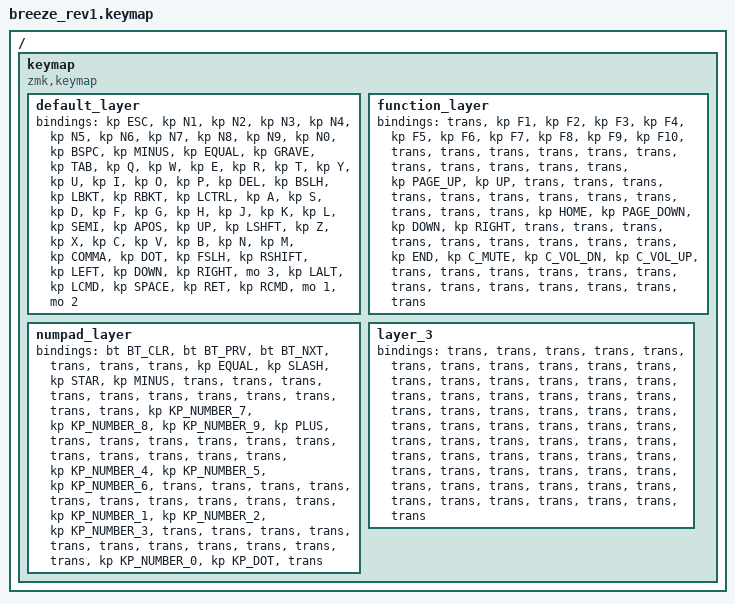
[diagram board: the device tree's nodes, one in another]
/*
 * Copyright (c) 2022 The ZMK Contributors
 *
 * SPDX-License-Identifier: MIT
 */

#include <behaviors.dtsi>
#include <dt-bindings/zmk/bt.h>
#include <dt-bindings/zmk/keys.h>

/ {
    keymap {
        compatible = "zmk,keymap";

        default_layer {
            // Ref: https://zmkfirmware.dev/docs/codes/
            // ---  MAIN  -----------------------------------------------------------------------------------------------------------------------
            // |    ESC    |     1     |     2     |     3      |      4      |      5     |                           |      6      |      7     |      8      |      9     |     0    |    BSPC    | |    -/_    |     =/+     |    GRAVE    |
            // |    TAB    |     Q     |     W     |     E      |      R      |      T     |                           |      Y      |      U     |      I      |      O     |     P    |    DEL     | |     \     |      [      |      ]      |
            // |   LCTRL   |     A     |     S     |     D      |      F      |      G     |                           |      H      |      J     |      K      |      L     |     ;    |     '      | |           |      UP     |             |
            // |   SHIFT   |     Z     |     X     |     C      |      V      |      B     |                           |      N      |      M     |      ,      |      .     |     /    |   RSHIFT   | |     L     |      DN     |      R      |
            //                                     |   NUMPAD   |     LALT    |    LCMD    |   SPACE    |  |   ENTER   |   FUNCTION  |  MACOS APP |  MACOS LANG |

            bindings = <
&kp ESC  &kp N1  &kp N2  &kp N3  &kp N4  &kp N5  &kp N6  &kp N7  &kp N8  &kp N9  &kp N0  &kp BSPC  &kp MINUS  &kp EQUAL  &kp GRAVE  &kp TAB  &kp Q  &kp W  &kp E  &kp R  &kp T  &kp Y  &kp U  &kp I  &kp O  &kp P  &kp DEL  &kp BSLH  &kp LBKT  &kp RBKT  &kp LCTRL  &kp A  &kp S  &kp D  &kp F  &kp G  &kp H  &kp J  &kp K  &kp L  &kp SEMI  &kp APOS  &kp UP  &kp LSHFT  &kp Z  &kp X  &kp C  &kp V  &kp B  &kp N  &kp M  &kp COMMA  &kp DOT  &kp FSLH  &kp RSHIFT  &kp LEFT  &kp DOWN  &kp RIGHT  &mo 3  &kp LALT  &kp LCMD  &kp SPACE  &kp RET  &kp RCMD  &mo 1  &mo 2
            >;
        };

        function_layer {
            // ---  FUNCTION  -------------------------------------------------------------------------------------------------------------------
            // | BT Clear  |  BT Prev  |  BT Next  |            |             |            |                           |             |            |             |            |          |            | |           |             |             |
            // |           |           |           |            |             |            |                           |             |            |     UP      |            |          |            | |           |             |             |
            // |           |           |           |            |             |            |                           |             |    LEFT    |    DOWN     |   RIGHT    |          |            | |           |             |             |
            // |           |           |           |            |             |            |                           |             |    MUTE    |  VOL DOWN   |   VOL UP   |          |            | |           |             |             |
            //                                     |            |             |            |            |  |           |             |            |             |

            bindings = <
&trans  &kp F1  &kp F2  &kp F3  &kp F4  &kp F5  &kp F6  &kp F7  &kp F8  &kp F9  &kp F10  &trans  &trans  &trans  &trans  &trans  &trans  &trans  &trans  &trans  &trans  &trans  &kp PAGE_UP  &kp UP  &trans  &trans  &trans  &trans  &trans  &trans  &trans  &trans  &trans  &trans  &trans  &trans  &kp HOME  &kp PAGE_DOWN  &kp DOWN  &kp RIGHT  &trans  &trans  &trans  &trans  &trans  &trans  &trans  &trans  &trans  &kp END  &kp C_MUTE  &kp C_VOL_DN  &kp C_VOL_UP  &trans  &trans  &trans  &trans  &trans  &trans  &trans  &trans  &trans  &trans  &trans  &trans  &trans
            >;
        };

        numpad_layer {
            // ---  NUMPAD  -------------------------------------------------------------------------------------------------------------------
            // |           |           |           |            |             |            |                           |       =       |      /       |      *       |      -     |          |            | |           |             |             |
            // |           |           |           |            |             |            |                           |       7       |      8       |      9       |      +     |          |            | |           |             |             |
            // |           |           |           |            |             |            |                           |       4       |      5       |      6       |            |          |            | |           |             |             |
            // |           |           |           |            |             |            |                           |       1       |      2       |      3       |            |          |            | |           |             |             |
            //                                     |            |             |            |            |  |           |       0       |      .       |              |

            bindings = <
&bt BT_CLR  &bt BT_PRV  &bt BT_NXT  &trans  &trans  &trans  &kp EQUAL  &kp SLASH  &kp STAR  &kp MINUS  &trans  &trans  &trans  &trans  &trans  &trans  &trans  &trans  &trans  &trans  &trans  &kp KP_NUMBER_7  &kp KP_NUMBER_8  &kp KP_NUMBER_9  &kp PLUS  &trans  &trans  &trans  &trans  &trans  &trans  &trans  &trans  &trans  &trans  &trans  &kp KP_NUMBER_4  &kp KP_NUMBER_5  &kp KP_NUMBER_6  &trans  &trans  &trans  &trans  &trans  &trans  &trans  &trans  &trans  &trans  &kp KP_NUMBER_1  &kp KP_NUMBER_2  &kp KP_NUMBER_3  &trans  &trans  &trans  &trans  &trans  &trans  &trans  &trans  &trans  &trans  &trans  &kp KP_NUMBER_0  &kp KP_DOT  &trans
            >;
        };

        layer_3 {
            bindings = <
&trans  &trans  &trans  &trans  &trans  &trans  &trans  &trans  &trans  &trans  &trans  &trans  &trans  &trans  &trans  &trans  &trans  &trans  &trans  &trans  &trans  &trans  &trans  &trans  &trans  &trans  &trans  &trans  &trans  &trans  &trans  &trans  &trans  &trans  &trans  &trans  &trans  &trans  &trans  &trans  &trans  &trans  &trans  &trans  &trans  &trans  &trans  &trans  &trans  &trans  &trans  &trans  &trans  &trans  &trans  &trans  &trans  &trans  &trans  &trans  &trans  &trans  &trans  &trans  &trans  &trans
            >;
        };
    };
};
